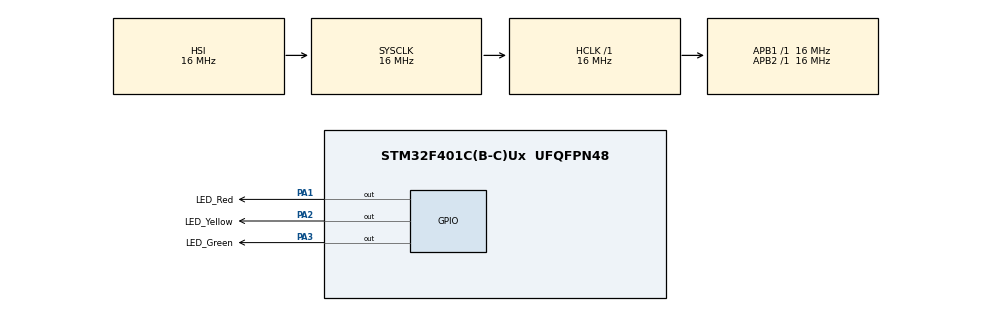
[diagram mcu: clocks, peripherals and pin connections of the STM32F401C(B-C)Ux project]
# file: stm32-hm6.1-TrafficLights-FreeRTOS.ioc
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FREERTOS.Tasks01=defaultTask,8,128,StartDefaultTask,Default,NULL,Dynamic,NULL,NULL
FREERTOS.configUSE_NEWLIB_REENTRANT=1
Mcu.Family=STM32F4
Mcu.Name=STM32F401C(B-C)Ux
Mcu.Package=UFQFPN48
NVIC.PriorityGroup=NVIC_PRIORITYGROUP_4
NVIC.TIM1_UP_TIM10_IRQn=true\:15\:0\:false\:false\:true\:false\:false\:true\:true
NVIC.TimeBase=TIM1_UP_TIM10_IRQn
NVIC.TimeBaseIP=TIM1
PA1.GPIO_Label=LED_Red
PA1.Signal=GPIO_Output
PA2.GPIO_Label=LED_Yellow
PA2.Signal=GPIO_Output
PA3.GPIO_Label=LED_Green
PA3.Signal=GPIO_Output
ProjectManager.HeapSize=0x200
ProjectManager.StackSize=0x400
ProjectManager.TargetToolchain=STM32CubeIDE
RCC.AHBFreq_Value=16000000
RCC.APB1Freq_Value=16000000
RCC.APB2Freq_Value=16000000
RCC.CortexFreq_Value=16000000
RCC.HSE_VALUE=25000000
RCC.HSI_VALUE=16000000
RCC.LSE_VALUE=32768
RCC.SYSCLKFreq_VALUE=16000000
RCC.VCOOutputFreq_Value=192000000
VP_FREERTOS_VS_CMSIS_V2.Mode=CMSIS_V2
VP_SYS_VS_tim1.Mode=TIM1
board=custom

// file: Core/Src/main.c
/* USER CODE BEGIN Header */
/**
  ******************************************************************************
  * @file           : main.c
  * @brief          : Main program body
  ******************************************************************************
  * @attention
  *
  * Copyright (c) 2026 STMicroelectronics.
  * All rights reserved.
  *
  * This software is licensed under terms that can be found in the LICENSE file
  * in the root directory of this software component.
  * If no LICENSE file comes with this software, it is provided AS-IS.
  *
  ******************************************************************************
  */
/* USER CODE END Header */
#include "main.h"
#include "cmsis_os.h"

/* USER CODE BEGIN Includes */
#include "app.h"
/* USER CODE END Includes */

/* Definitions for defaultTask */
osThreadId_t defaultTaskHandle;
const osThreadAttr_t defaultTask_attributes = {
  .name = "defaultTask",
  .stack_size = 128 * 4,
  .priority = (osPriority_t) osPriorityLow,
};

void SystemClock_Config(void);
static void MX_GPIO_Init(void);
void StartDefaultTask(void *argument);

int main(void)
{

  /* MCU Configuration--------------------------------------------------------*/

  /* Reset of all peripherals, Initializes the Flash interface and the Systick. */
  HAL_Init();

  /* Configure the system clock */
  SystemClock_Config();

  /* Initialize all configured peripherals */
  MX_GPIO_Init();

  /* Init scheduler */
  osKernelInitialize();

  /* Create the thread(s) */
  /* creation of defaultTask */
  defaultTaskHandle = osThreadNew(StartDefaultTask, NULL, &defaultTask_attributes);

  /* USER CODE BEGIN RTOS_EVENTS */

  // delete generated task from CubeMX
  if (defaultTaskHandle != NULL) {
     osThreadTerminate(defaultTaskHandle);
     defaultTaskHandle = NULL;
  }
  app_start();

  /* USER CODE END RTOS_EVENTS */

  /* Start scheduler */
  osKernelStart();

  /* We should never get here as control is now taken by the scheduler */

  /* Infinite loop */
  while (1)
  {

  }
}

void SystemClock_Config(void)
{
  RCC_OscInitTypeDef RCC_OscInitStruct = {0};
  RCC_ClkInitTypeDef RCC_ClkInitStruct = {0};

  /** Configure the main internal regulator output voltage
  */
  __HAL_RCC_PWR_CLK_ENABLE();
  __HAL_PWR_VOLTAGESCALING_CONFIG(PWR_REGULATOR_VOLTAGE_SCALE2);

  /** Initializes the RCC Oscillators according to the specified parameters
  * in the RCC_OscInitTypeDef structure.
  */
  RCC_OscInitStruct.OscillatorType = RCC_OSCILLATORTYPE_HSI;
  RCC_OscInitStruct.HSIState = RCC_HSI_ON;
  RCC_OscInitStruct.HSICalibrationValue = RCC_HSICALIBRATION_DEFAULT;
  RCC_OscInitStruct.PLL.PLLState = RCC_PLL_NONE;
  if (HAL_RCC_OscConfig(&RCC_OscInitStruct) != HAL_OK)
  {
    Error_Handler();
  }

  /** Initializes the CPU, AHB and APB buses clocks
  */
  RCC_ClkInitStruct.ClockType = RCC_CLOCKTYPE_HCLK|RCC_CLOCKTYPE_SYSCLK
                              |RCC_CLOCKTYPE_PCLK1|RCC_CLOCKTYPE_PCLK2;
  RCC_ClkInitStruct.SYSCLKSource = RCC_SYSCLKSOURCE_HSI;
  RCC_ClkInitStruct.AHBCLKDivider = RCC_SYSCLK_DIV1;
  RCC_ClkInitStruct.APB1CLKDivider = RCC_HCLK_DIV1;
  RCC_ClkInitStruct.APB2CLKDivider = RCC_HCLK_DIV1;

  if (HAL_RCC_ClockConfig(&RCC_ClkInitStruct, FLASH_LATENCY_0) != HAL_OK)
  {
    Error_Handler();
  }
}

static void MX_GPIO_Init(void)
{
  GPIO_InitTypeDef GPIO_InitStruct = {0};

  /* GPIO Ports Clock Enable */
  __HAL_RCC_GPIOA_CLK_ENABLE();

  /*Configure GPIO pin Output Level */
  HAL_GPIO_WritePin(GPIOA, LED_Red_Pin|LED_Yellow_Pin|LED_Green_Pin, GPIO_PIN_RESET);

  /*Configure GPIO pins : LED_Red_Pin LED_Yellow_Pin LED_Green_Pin */
  GPIO_InitStruct.Pin = LED_Red_Pin|LED_Yellow_Pin|LED_Green_Pin;
  GPIO_InitStruct.Mode = GPIO_MODE_OUTPUT_PP;
  GPIO_InitStruct.Pull = GPIO_NOPULL;
  GPIO_InitStruct.Speed = GPIO_SPEED_FREQ_LOW;
  HAL_GPIO_Init(GPIOA, &GPIO_InitStruct);

}

void StartDefaultTask(void *argument)
{
  /* USER CODE BEGIN 5 */
  /* Infinite loop */
  for(;;)
  {
    osDelay(1000);
  }
  /* USER CODE END 5 */
}

void HAL_TIM_PeriodElapsedCallback(TIM_HandleTypeDef *htim)
{
  if (htim->Instance == TIM1)
  {
    HAL_IncTick();
  }
}

void Error_Handler(void)
{
  __disable_irq();
  while (1)
  {
  }
}
